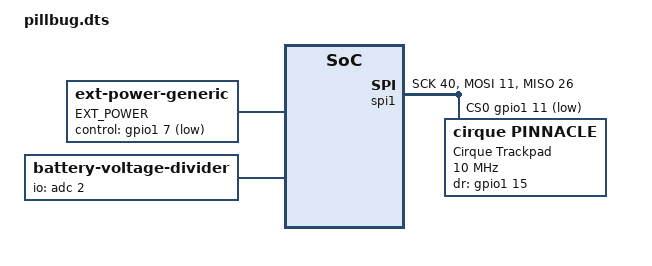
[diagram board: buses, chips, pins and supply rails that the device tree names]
/*
 * Copyright (c) 2022 The ZMK Contributors
 *
 * SPDX-License-Identifier: MIT
 */

/dts-v1/;
#include "pillbug.dtsi"

/ {
    chosen {
        zmk,battery = &vbatt;
    };

    ext-power {
        compatible = "zmk,ext-power-generic";
        label = "EXT_POWER";
        control-gpios = <&gpio1 7 GPIO_ACTIVE_LOW>;
        init-delay-ms = <50>;
    };

    vbatt: vbatt {
        compatible = "zmk,battery-voltage-divider";
        label = "BATTERY";
        io-channels = <&adc 2>;
        output-ohms = <2000000>;
        full-ohms = <(2000000 + 820000)>;
    };
};


&spi1 {
    compatible = "nordic,nrf-spim";
    status = "okay";
    sck-pin = <40>;
    mosi-pin = <11>;
    miso-pin = <26>;

    cs-gpios = <&gpio1 11 GPIO_ACTIVE_LOW>;
    trackpad@0 {
        compatible = "cirque,pinnacle";
        status = "okay";
        reg = <0>;
        spi-max-frequency = <10000000>;
        dr-gpios = <&gpio1 15 GPIO_ACTIVE_HIGH>;
        invert-x;
        sleep;
        /* no-taps; */
        label = "Cirque Trackpad";
    };
};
